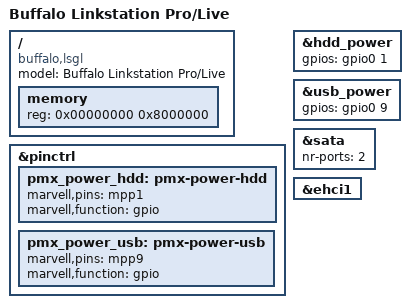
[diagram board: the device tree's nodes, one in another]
/dts-v1/;
#include "orion5x-linkstation.dtsi"
#include <dt-bindings/gpio/gpio.h>
/ {
	model = "Buffalo Linkstation Pro/Live";
	compatible = "buffalo,lsgl", "marvell,orion5x-88f5182", "marvell,orion5x";
	memory {  
		device_type = "memory";
		reg = <0x00000000 0x8000000>;
	};
};
&pinctrl {
	pmx_power_hdd: pmx-power-hdd {
		marvell,pins = "mpp1";
		marvell,function = "gpio";
	};
	pmx_power_usb: pmx-power-usb {
		marvell,pins = "mpp9";
		marvell,function = "gpio";
	};
};
&hdd_power {
	gpios = <&gpio0 1 GPIO_ACTIVE_HIGH>;
};
&usb_power {
	gpios = <&gpio0 9 GPIO_ACTIVE_HIGH>;
};
&sata {
	nr-ports = <2>;
};
&ehci1 {
	status = "okay";
};
